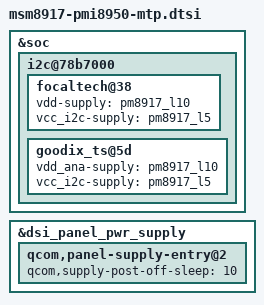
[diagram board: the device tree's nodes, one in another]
/*
 * Copyright (c) 2017, The Linux Foundation. All rights reserved.
 *
 * This program is free software; you can redistribute it and/or modify
 * it under the terms of the GNU General Public License version 2 and
 * only version 2 as published by the Free Software Foundation.
 *
 * This program is distributed in the hope that it will be useful,
 * but WITHOUT ANY WARRANTY; without even the implied warranty of
 * MERCHANTABILITY or FITNESS FOR A PARTICULAR PURPOSE.  See the
 * GNU General Public License for more details.
 */

&soc {
	i2c@78b7000 {
		focaltech@38 {
            vdd-supply = <&pm8917_l10>;
		    vcc_i2c-supply = <&pm8917_l5>;
        };

        goodix_ts@5d {
			vdd_ana-supply = <&pm8917_l10>;
			vcc_i2c-supply = <&pm8917_l5>;
        };
    };
};

&dsi_panel_pwr_supply {
	qcom,panel-supply-entry@2 {
		qcom,supply-post-off-sleep = <10>;
	};
};
